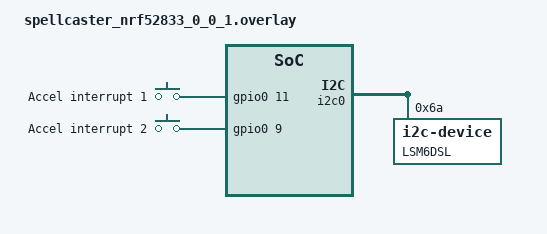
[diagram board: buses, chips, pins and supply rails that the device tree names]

/ {
	interrupts {
		compatible = "gpio-keys";
		int_1: int_1 {
			// P0.11.
			gpios = <&gpio0 11 (GPIO_PULL_DOWN | GPIO_ACTIVE_HIGH)>;
			label = "Accel interrupt 1";
		};
		int_2: int_2 {
			// P0.9.
			gpios = <&gpio0 9 (GPIO_PULL_DOWN | GPIO_ACTIVE_HIGH)>;
			label = "Accel interrupt 2";
		};
	};
};

&i2c0 {
	compatible = "nordic,nrf-twi";
	status = "okay";
	pinctrl-0 = <&i2c0_default>;
	pinctrl-1 = <&i2c0_sleep>;
	pinctrl-names = "default", "sleep";

	lsm6dsl: lsm6dsl@6a {
		compatible = "i2c-device";
		reg = <0x6a>;
		status = "okay";
		label = "LSM6DSL";
	};
};
